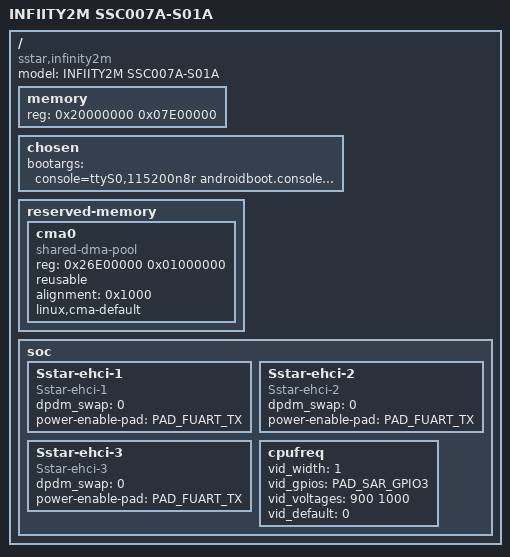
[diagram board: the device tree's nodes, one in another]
/*
 * Copyright (c) 2014 MundoReader S.L.
 * Author: Matthias Brugger <matthias.bgg@gmail.com>
 *
 * This program is free software; you can redistribute it and/or modify
 * it under the terms of the GNU General Public License as published by
 * the Free Software Foundation; either version 2 of the License, or
 * (at your option) any later version.
 *
 * This program is distributed in the hope that it will be useful,
 * but WITHOUT ANY WARRANTY; without even the implied warranty of
 * MERCHANTABILITY or FITNESS FOR A PARTICULAR PURPOSE.  See the
 * GNU General Public License for more details.
 */

/dts-v1/;
#include "infinity2m.dtsi"

/ {
    model = "INFIITY2M SSC007A-S01A";
    compatible = "sstar,infinity2m";

    memory {
        reg = <0x20000000 0x07E00000>;
    };

    chosen {
        bootargs = "console=ttyS0,115200n8r androidboot.console=ttyS0 root=/dev/mtdblock2 init=/linuxrc";
    };

/*!!IMPORTANT!! The reserved memory must be 1MB aligned*/
    reserved-memory {
        #address-cells = <1>;
        #size-cells = <1>;
        ranges;

        cma0 {
            compatible = "shared-dma-pool";
            reg = <0x26E00000 0x01000000>;
            reusable;
            alignment = <0x1000>;
            linux,cma-default;
        };
    };

    soc {
        Sstar-ehci-1 {
            compatible = "Sstar-ehci-1";
            dpdm_swap=<0>;
            power-enable-pad = <PAD_FUART_TX>;
        };
        Sstar-ehci-2 {
            compatible = "Sstar-ehci-2";
            dpdm_swap=<0>;
            power-enable-pad = <PAD_FUART_TX>;
        };
        Sstar-ehci-3 {
            compatible = "Sstar-ehci-3";
            dpdm_swap=<0>;
            power-enable-pad = <PAD_FUART_TX>;
        };
        cpufreq {
            vid_width = <1>;
            vid_gpios = <PAD_SAR_GPIO3>;
            vid_voltages = <900 1000>;  //2b'00 2b'01
            vid_default = <0>;  //2b'00
        };
    };
};
